# CEC1734_S0_2ZW register map
Vendor: Microchip Technology; Series: CEC; File version: 0
CPU: CM4 r1p0, little endian, MPU, FPU, 3 interrupt priority bits, 196 interrupts
Registers are 32-bit, read-write, reset 0x0 unless marked. A register's access mark holds for its fields unless they carry their own. Offsets are from the block's base; [hi:lo] are bit positions; {n}, {i} and the like mark numbered series.

## RTOS — RTOS is a 32-bit timer designed to operate on the 32kHz oscillator which is available during all chip sleep states.
Base 0x40007400; register names take the prefix RTOS_
0x00 CNT — RTOS Timer Count Register.
  [31:0] CNTR — This register contains the current value of the RTOS Timer counter. This register should be read as a DWORD. There is no latching mechanism of the upper bytes implemented if the register is accessed as a byte or word. Reading the register with byte or word operations may give incorrect results.
0x04 PRLD — RTOS Timer Preload Register
  [31:0] PRELOAD — The this register is loaded into the RTOS Timer counter either when the TIMER_START bit is written with a 1, or when the timer counter counts down to 0 and the AUTO_RELOAD bit is 1. This register must be programmed with a new count value before the TIMER_START bit is set to 1. If this register is updated while the counter is operating, the new count value will only take effect if the counter transitions form 1 to 0 while the AUTO_RELOAD bit is set.
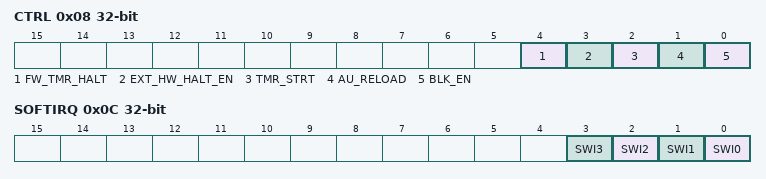
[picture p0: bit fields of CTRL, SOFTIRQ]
0x08 CTRL — RTOS Timer Control Register
  [4] FW_TMR_HALT — 1=The timer counter is halted. If the counter was running, clearing this bit will restart the counter from the value at which it halted 0=The timer counter, if enabled, will continue to run
  [3] EXT_HW_HALT_EN — 1=The timer counter is halted when the external HALT signal is asserted. Counting is always enabled if HALT is de-asserted. 0=The HALT signal does not affect the RTOS Timer
  [2] TMR_STRT — Writing a 1 to this bit will load the timer counter with the RTOS Timer Preload Register and start counting. If the Preload Register is 0, counting will not start and this bit will be cleared to 0. Writing a 0 to this bit will halt the counter and clear its contents to 0. The RTOS timer interrupt will not be generated. This bit is automatically cleared if the AUTO_RELOAD bit is 0 and the timer counter transitions from 1 to 0.
  [1] AU_RELOAD — 1=The the RTOS Timer Preload Register is loaded into the timer counter and the counter is restarted when the counter transitions from 1 to 0 0=The timer counter halts when it transitions from 1 to 0 and will not restart.
  [0] BLK_EN — 1=RTOS timer counter is enabled 0=RTOS timer disabled. All register bits are reset to their default state
0x0C SOFTIRQ wo — Soft Interrupt Register
  [n] SWI{n} (n=0..3) — Software Interrupt. A write of a '1' to this bit will generate an SWI interrupt to the EC. Writes of a '0' have no effect. Reads return '0'.

## PWM0 — The PWM block generates an arbitrary duty cycle output at frequencies from less than 0.1 Hz to 24 MHz.
Base 0x40005800; register names take the prefix PWM_
0x00 CNT_ON — This field determines both the frequency and duty cycle of the PWM signal. Setting this field to a value of n will cause the On time of the PWM to be n+1 cycles of the PWM Clock Source. When this field is set to zero and the PWMX_COUNTER_OFF_TIME is not set to zero, the PWM_OUTPUT is held low (Full Off).
0x04 CNT_OFF reset 0xFFFF — This field determine both the frequency and duty cycle of the PWM signal. Setting this field to a value of n will cause the Off time of the PWM to be n+1 cycles of the PWM Clock Source. When this field is set to zero, the PWM_OUTPUT is held high (Full On).
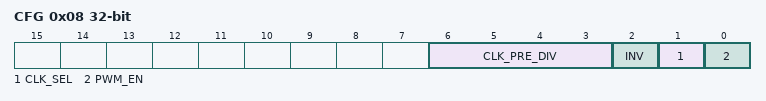
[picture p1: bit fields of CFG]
0x08 CFG — PWMx CONFIGURATION REGISTER
  [6:3] CLK_PRE_DIV — The Clock source for the 16-bit down counter (see PWMx Counter ON Time Register and PWMx Counter OFF Time Register) is determined by bit D1 of this register. The Clock source is then divided by the value of Pre-Divider+1 and the resulting signal determines the rate at which the down counter will be decremented. For example, a Pre-Divider value of 1 divides the input clock by 2 and a value of 2 divides the input clock by 3. A Pre-Divider of 0 will disable the Pre-Divider option.
  [2] INV — 1= PWM_OUTPUT ON State is active low; 0=PWM_OUTPUT ON State is active high.
  [1] CLK_SEL — This bit determines the clock source used by the PWM duty cycle and frequency control logic. 1=CLOCK_LOW 0=CLOCK_HIGH
  [0] PWM_EN — When the PWM_ENABLE is set to 0 the internal counters are reset and the internal state machine is set to the OFF state. In addition, the PWM_OUTPUT signal is set to the inactive state as determined by the Invert bit. The PWMx Counter ON Time Register and PWMx Counter OFF Time Register are not affected by the PWM_ENABLE bit and may be read and written while the PWM enable bit is 0. 1=Enabled (default); 0=Disabled (gates clocks to save power).
